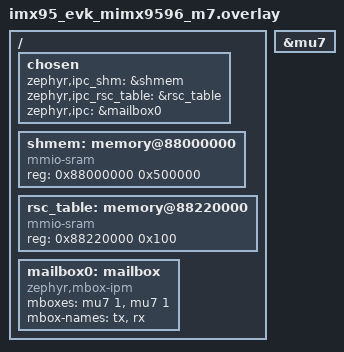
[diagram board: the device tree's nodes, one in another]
/*
 * Copyright 2025 NXP
 *
 * SPDX-License-Identifier: Apache-2.0
 */

/ {
	chosen {
		/*
		 * shared memory reserved for the inter-processor communication
		 */
		zephyr,ipc_shm = &shmem;
		zephyr,ipc_rsc_table = &rsc_table;
		zephyr,ipc = &mailbox0;
	};

	shmem: memory@88000000 {
		compatible = "mmio-sram";
		reg = <0x88000000 0x500000>;
	};

	rsc_table: memory@88220000 {
		compatible = "mmio-sram";
		reg = <0x88220000 0x100>;
	};

	mailbox0: mailbox {
		compatible = "zephyr,mbox-ipm";
		mboxes = <&mu7 1>, <&mu7 1>;
		mbox-names = "tx", "rx";
		status = "okay";
	};
};

&mu7 {
	status = "okay";
};
